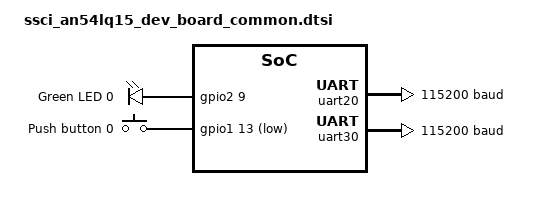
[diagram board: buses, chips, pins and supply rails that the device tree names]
/*
 * Copyright (c) 2024 Nordic Semiconductor ASA
 * Copyright (c) 2025 Raytac Corporation.
 *
 * SPDX-License-Identifier: Apache-2.0
 */

#include "ssci_an54lq15_dev_board-pinctrl.dtsi"

/ {
	leds {
		compatible = "gpio-leds";

		led0: led_0 {
			gpios = <&gpio2 9 GPIO_ACTIVE_HIGH>;
			label = "Green LED 0";
		};
	};

	buttons {
		compatible = "gpio-keys";

		button0: button_0 {
			gpios = <&gpio1 13 (GPIO_PULL_UP | GPIO_ACTIVE_LOW)>;
			label = "Push button 0";
			zephyr,code = <INPUT_KEY_0>;
		};
	};

	aliases {
		led0 = &led0;
		sw0 = &button0;
		watchdog0 = &wdt31;
	};
};

&uart20 {
	current-speed = <115200>;
	pinctrl-0 = <&uart20_default>;
	pinctrl-1 = <&uart20_sleep>;
	pinctrl-names = "default", "sleep";
};

&uart30 {
	current-speed = <115200>;
	pinctrl-0 = <&uart30_default>;
	pinctrl-1 = <&uart30_sleep>;
	pinctrl-names = "default", "sleep";
};

&hfxo {
	startup-time-us = <854>;
};

/* Get a node label for wi-fi spi to use in shield files */
wifi_spi: &spi22 {};
